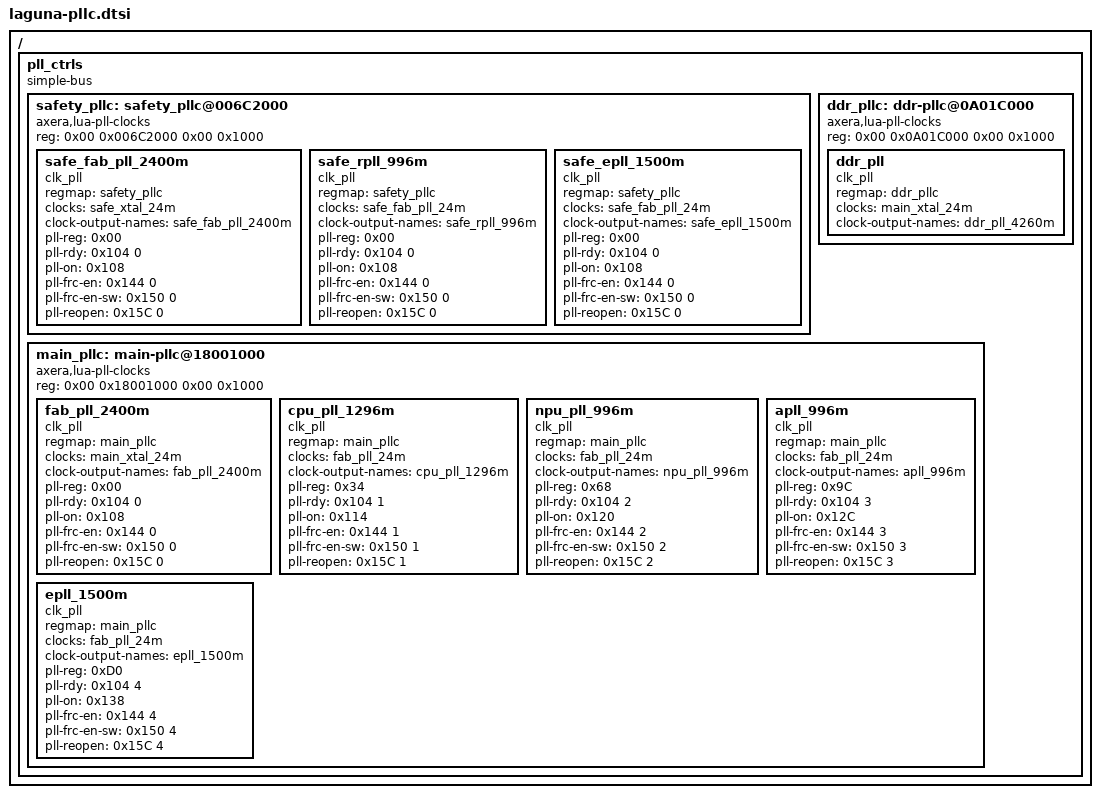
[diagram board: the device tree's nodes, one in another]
/* SPDX-License-Identifier: GPL-2.0+
 *
 * Device Tree Source for Laguna PLL Ctrl
 *
 * Copyright (C) 2024 Charleye <wangkart@aliyun.com>
 */

/ {
	pll_ctrls {
		compatible = "simple-bus";
		#address-cells = <2>;
		#size-cells = <2>;

		safety_pllc: safety_pllc@006C2000 {
			compatible = "axera,lua-pll-clocks";
			reg = <0x00 0x006C2000 0x00 0x1000>;
			#address-cells = <1>;
			#size-cells = <1>;

			safe_fab_pll_2400m: safe_fab_pll_2400m {
				compatible = "clk_pll";
				regmap = <&safety_pllc>;
				clocks = <&safe_xtal_24m>;
				clock-names = "safe_xtal_24m";
				#clock-cells = <0>;
				clock-output-names = "safe_fab_pll_2400m";
				pll-reg = <0x00>;
				pll-rdy = <0x104 0>;
				pll-on = <0x108>;
				pll-frc-en = <0x144 0>;
				pll-frc-en-sw = <0x150 0>;
				pll-reopen = <0x15C 0>;
			};

			safe_rpll_996m: safe_rpll_996m {
				compatible = "clk_pll";
				regmap = <&safety_pllc>;
				clocks = <&safe_fab_pll_24m>;
				clock-names = "safe_fab_pll_24m";
				#clock-cells = <0>;
				clock-output-names = "safe_rpll_996m";
				pll-reg = <0x00>;
				pll-rdy = <0x104 0>;
				pll-on = <0x108>;
				pll-frc-en = <0x144 0>;
				pll-frc-en-sw = <0x150 0>;
				pll-reopen = <0x15C 0>;
			};

			safe_epll_1500m: safe_epll_1500m {
				compatible = "clk_pll";
				regmap = <&safety_pllc>;
				clocks = <&safe_fab_pll_24m>;
				clock-names = "safe_fab_pll_24m";
				#clock-cells = <0>;
				clock-output-names = "safe_epll_1500m";
				pll-reg = <0x00>;
				pll-rdy = <0x104 0>;
				pll-on = <0x108>;
				pll-frc-en = <0x144 0>;
				pll-frc-en-sw = <0x150 0>;
				pll-reopen = <0x15C 0>;
			};
		};

		ddr_pllc: ddr-pllc@0A01C000 {
			compatible = "axera,lua-pll-clocks";
			reg = <0x00 0x0A01C000 0x00 0x1000>;
			#address-cells = <1>;
			#size-cells = <1>;

			ddr_pll: ddr_pll {
				compatible = "clk_pll";
				regmap = <&ddr_pllc>;
				clocks = <&main_xtal_24m>;
				clock-names = "main_xtal_24m";
				#clock-cells = <0>;
				clock-output-names = "ddr_pll_4260m";
			};
		};

		main_pllc: main-pllc@18001000 {
			compatible = "axera,lua-pll-clocks";
			reg = <0x00 0x18001000 0x00 0x1000>;
			#address-cells = <1>;
			#size-cells = <1>;

			fab_pll_2400m: fab_pll_2400m {
				compatible = "clk_pll";
				regmap = <&main_pllc>;
				clocks = <&main_xtal_24m>;
				clock-names = "main_xtal_24m";
				#clock-cells = <0>;
				clock-output-names = "fab_pll_2400m";
				pll-reg = <0x00>;
				pll-rdy = <0x104 0>;
				pll-on = <0x108>;
				pll-frc-en = <0x144 0>;
				pll-frc-en-sw = <0x150 0>;
				pll-reopen = <0x15C 0>;
			};

			cpu_pll_1296m: cpu_pll_1296m {
				compatible = "clk_pll";
				regmap = <&main_pllc>;
				clocks = <&fab_pll_24m>;
				clock-names = "fab_pll_24m";
				#clock-cells = <0>;
				clock-output-names = "cpu_pll_1296m";
				pll-reg = <0x34>;
				pll-rdy = <0x104 1>;
				pll-on = <0x114>;
				pll-frc-en = <0x144 1>;
				pll-frc-en-sw = <0x150 1>;
				pll-reopen = <0x15C 1>;
			};

			npu_pll_996m: npu_pll_996m {
				compatible = "clk_pll";
				regmap = <&main_pllc>;
				clocks = <&fab_pll_24m>;
				clock-names = "fab_pll_24m";
				#clock-cells = <0>;
				clock-output-names = "npu_pll_996m";
				pll-reg = <0x68>;
				pll-rdy = <0x104 2>;
				pll-on = <0x120>;
				pll-frc-en = <0x144 2>;
				pll-frc-en-sw = <0x150 2>;
				pll-reopen = <0x15C 2>;
			};

			apll_996m: apll_996m {
				compatible = "clk_pll";
				regmap = <&main_pllc>;
				clocks = <&fab_pll_24m>;
				clock-names = "fab_pll_24m";
				#clock-cells = <0>;
				clock-output-names = "apll_996m";
				pll-reg = <0x9C>;
				pll-rdy = <0x104 3>;
				pll-on = <0x12C>;
				pll-frc-en = <0x144 3>;
				pll-frc-en-sw = <0x150 3>;
				pll-reopen = <0x15C 3>;
			};

			epll_1500m: epll_1500m {
				compatible = "clk_pll";
				regmap = <&main_pllc>;
				clocks = <&fab_pll_24m>;
				clock-names = "fab_pll_24m";
				#clock-cells = <0>;
				clock-output-names = "epll_1500m";
				pll-reg = <0xD0>;
				pll-rdy = <0x104 4>;
				pll-on = <0x138>;
				pll-frc-en = <0x144 4>;
				pll-frc-en-sw = <0x150 4>;
				pll-reopen = <0x15C 4>;
			};
		};
	};
};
